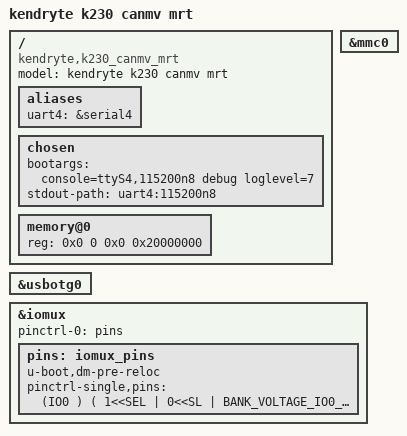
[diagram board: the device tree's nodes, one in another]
/* Copyright (c) 2023, Canaan Bright Sight Co., Ltd
 *
 * Redistribution and use in source and binary forms, with or without
 * modification, are permitted provided that the following conditions are met:
 * 1. Redistributions of source code must retain the above copyright
 * notice, this list of conditions and the following disclaimer.
 * 2. Redistributions in binary form must reproduce the above copyright
 * notice, this list of conditions and the following disclaimer in the
 * documentation and/or other materials provided with the distribution.
 *
 * THIS SOFTWARE IS PROVIDED BY THE COPYRIGHT HOLDERS AND
 * CONTRIBUTORS "AS IS" AND ANY EXPRESS OR IMPLIED WARRANTIES,
 * INCLUDING, BUT NOT LIMITED TO, THE IMPLIED WARRANTIES OF
 * MERCHANTABILITY AND FITNESS FOR A PARTICULAR PURPOSE ARE
 * DISCLAIMED. IN NO EVENT SHALL THE COPYRIGHT HOLDER OR
 * CONTRIBUTORS BE LIABLE FOR ANY DIRECT, INDIRECT, INCIDENTAL,
 * SPECIAL, EXEMPLARY, OR CONSEQUENTIAL DAMAGES (INCLUDING,
 * BUT NOT LIMITED TO, PROCUREMENT OF SUBSTITUTE GOODS OR
 * SERVICES; LOSS OF USE, DATA, OR PROFITS; OR BUSINESS
 * INTERRUPTION) HOWEVER CAUSED AND ON ANY THEORY OF LIABILITY,
 * WHETHER IN CONTRACT, STRICT LIABILITY, OR TORT (INCLUDING
 * NEGLIGENCE OR OTHERWISE) ARISING IN ANY WAY OUT OF THE USE
 * OF THIS SOFTWARE, EVEN IF ADVISED OF THE POSSIBILITY OF SUCH DAMAGE.
 */
/dts-v1/;
#include <dt-bindings/pinctrl/k230_evb.h>

/*
 * K230 CANMV MRT (K230_MAIN_1V3) board
 *
 * Bank voltage configuration from schematic K230_MAIN_1V3_20260420.pdf:
 *   IO0~IO1:   1V8 (fixed, OSPI domain)
 *   IO2~IO13:  1V8 (eMMC VCCQ=1V8, CAM0 I2C4=1V8)
 *   IO14~IO25: 3V3 (general IO, LCD, sensor)
 *   IO26~IO37: 1V8 (MMC1 WiFi SDIO, I2C3=1V8 domain per canmv_k230 ref)
 *   IO38~IO49: 3V3 (UART0, I2C1, GPIO)
 *   IO50~IO61: 3V3 (UART3, MMC1, WiFi)
 *   IO62~IO63: 1V8 (fixed)
 *
 * WARNING: Bank voltage MUST match board hardware.
 *          Incorrect configuration may permanently damage the chip!
 */
#define BANK_VOLTAGE_IO0_IO1	 K230_MSC_1V8
#define BANK_VOLTAGE_IO2_IO13	 K230_MSC_1V8
#define BANK_VOLTAGE_IO14_IO25	 K230_MSC_3V3
#define BANK_VOLTAGE_IO26_IO37	 K230_MSC_1V8
#define BANK_VOLTAGE_IO38_IO49	 K230_MSC_3V3
#define BANK_VOLTAGE_IO50_IO61	 K230_MSC_3V3
#define BANK_VOLTAGE_IO62_IO63	 K230_MSC_1V8
#include "k230.dtsi"

/ {
	model = "kendryte k230 canmv mrt";
	compatible = "kendryte,k230_canmv_mrt";

	aliases {
		uart4 = &serial4;
	};

	chosen {
		bootargs = "console=ttyS4,115200n8  debug loglevel=7";
		stdout-path = "uart4:115200n8";
	};

	memory@0 {
		device_type = "memory";
		reg = <
				0x0 0 0x0 0x20000000
			  >;
	};
};

&mmc0 {
	status = "okay";
};
&usbotg0 {
	status = "okay";
};
&iomux {
	pinctrl-names = "default";
	pinctrl-0 = <&pins>;

//	Please pay attention to the bank voltage! will damage the chip.
	pins: iomux_pins {
		u-boot,dm-pre-reloc;
		pinctrl-single,pins = <

		// OSPI CLK/DAT
		(IO0 ) ( 1<<SEL | 0<<SL | BANK_VOLTAGE_IO0_IO1 <<MSC | 1<<IE | 0<<OE | 0<<PU | 0<<PD | 0<<DS | 1<<ST )
		(IO1 ) ( 1<<SEL | 0<<SL | BANK_VOLTAGE_IO0_IO1 <<MSC | 1<<IE | 0<<OE | 0<<PU | 0<<PD | 0<<DS | 1<<ST )

		// JTAG / GPIO
		(IO2 ) ( 0<<SEL | 0<<SL | BANK_VOLTAGE_IO2_IO13 <<MSC | 1<<IE | 1<<OE | 0<<PU | 0<<PD | 7<<DS | 1<<ST )
		(IO3 ) ( 0<<SEL | 0<<SL | BANK_VOLTAGE_IO2_IO13 <<MSC | 1<<IE | 1<<OE | 0<<PU | 0<<PD | 7<<DS | 1<<ST )
		(IO4 ) ( 0<<SEL | 0<<SL | BANK_VOLTAGE_IO2_IO13 <<MSC | 1<<IE | 1<<OE | 0<<PU | 0<<PD | 7<<DS | 1<<ST )
		(IO5 ) ( 0<<SEL | 0<<SL | BANK_VOLTAGE_IO2_IO13 <<MSC | 1<<IE | 1<<OE | 0<<PU | 0<<PD | 7<<DS | 1<<ST )
		(IO6 ) ( 0<<SEL | 0<<SL | BANK_VOLTAGE_IO2_IO13 <<MSC | 1<<IE | 1<<OE | 0<<PU | 0<<PD | 7<<DS | 1<<ST )

		// CAM0_I2C4_SCL
		(IO7 ) ( 2<<SEL | 0<<SL | BANK_VOLTAGE_IO2_IO13 <<MSC | 1<<IE | 1<<OE | 0<<PU | 0<<PD | 7<<DS | 1<<ST )
		// CAM0_I2C4_SDA
		(IO8 ) ( 2<<SEL | 0<<SL | BANK_VOLTAGE_IO2_IO13 <<MSC | 1<<IE | 1<<OE | 0<<PU | 0<<PD | 7<<DS | 1<<ST )
		// CAM0_PWDN (GPIO9)
		(IO9 ) ( 0<<SEL | 0<<SL | BANK_VOLTAGE_IO2_IO13 <<MSC | 1<<IE | 1<<OE | 0<<PU | 0<<PD | 7<<DS | 1<<ST )
		// CAM0_RST (GPIO10)
		(IO10) ( 0<<SEL | 0<<SL | BANK_VOLTAGE_IO2_IO13 <<MSC | 1<<IE | 1<<OE | 0<<PU | 0<<PD | 7<<DS | 1<<ST )
		// GPIO11
		(IO11) ( 0<<SEL | 0<<SL | BANK_VOLTAGE_IO2_IO13 <<MSC | 1<<IE | 1<<OE | 0<<PU | 0<<PD | 7<<DS | 1<<ST )
		// GPIO12
		(IO12) ( 0<<SEL | 0<<SL | BANK_VOLTAGE_IO2_IO13 <<MSC | 1<<IE | 1<<OE | 0<<PU | 0<<PD | 7<<DS | 1<<ST )

		// CAM0_MCLK1
		(IO13) ( 1<<SEL | 0<<SL | BANK_VOLTAGE_IO2_IO13 <<MSC | 0<<IE | 1<<OE | 0<<PU | 0<<PD | 7<<DS | 0<<ST )

		// GPIO14 ~ GPIO16
		(IO14) ( 0<<SEL | 0<<SL | BANK_VOLTAGE_IO14_IO25 <<MSC | 1<<IE | 1<<OE | 0<<PU | 0<<PD | 7<<DS | 1<<ST )
		(IO15) ( 0<<SEL | 0<<SL | BANK_VOLTAGE_IO14_IO25 <<MSC | 1<<IE | 1<<OE | 0<<PU | 0<<PD | 7<<DS | 1<<ST )
		(IO16) ( 0<<SEL | 0<<SL | BANK_VOLTAGE_IO14_IO25 <<MSC | 1<<IE | 1<<OE | 0<<PU | 0<<PD | 7<<DS | 1<<ST )
		// LCD_BL (GPIO17)
		(IO17) ( 0<<SEL | 0<<SL | BANK_VOLTAGE_IO14_IO25 <<MSC | 1<<IE | 1<<OE | 0<<PU | 0<<PD | 15<<DS | 1<<ST )
		// GPIO18 ~ GPIO20
		(IO18) ( 0<<SEL | 0<<SL | BANK_VOLTAGE_IO14_IO25 <<MSC | 1<<IE | 1<<OE | 0<<PU | 0<<PD | 15<<DS | 1<<ST )
		(IO19) ( 0<<SEL | 0<<SL | BANK_VOLTAGE_IO14_IO25 <<MSC | 1<<IE | 1<<OE | 0<<PU | 0<<PD | 15<<DS | 1<<ST )
		(IO20) ( 0<<SEL | 0<<SL | BANK_VOLTAGE_IO14_IO25 <<MSC | 1<<IE | 1<<OE | 0<<PU | 0<<PD | 15<<DS | 1<<ST )
		// KEY (GPIO21)
		(IO21) ( 0<<SEL | 0<<SL | BANK_VOLTAGE_IO14_IO25 <<MSC | 1<<IE | 1<<OE | 0<<PU | 0<<PD | 15<<DS | 1<<ST )
		// TP_RST (GPIO22)
		(IO22) ( 0<<SEL | 0<<SL | BANK_VOLTAGE_IO14_IO25 <<MSC | 1<<IE | 1<<OE | 0<<PU | 0<<PD | 15<<DS | 1<<ST )
		// TP_INT (GPIO23)
		(IO23) ( 0<<SEL | 0<<SL | BANK_VOLTAGE_IO14_IO25 <<MSC | 1<<IE | 1<<OE | 0<<PU | 0<<PD | 15<<DS | 1<<ST )
		// LCD_RST (GPIO24)
		(IO24) ( 0<<SEL | 0<<SL | BANK_VOLTAGE_IO14_IO25 <<MSC | 1<<IE | 1<<OE | 0<<PU | 0<<PD | 15<<DS | 1<<ST )
		// FLASH_LED_PWM (GPIO25)
		(IO25) ( 0<<SEL | 0<<SL | BANK_VOLTAGE_IO14_IO25 <<MSC | 1<<IE | 1<<OE | 0<<PU | 0<<PD | 7<<DS | 1<<ST )

		// PDM_CLK (GPIO26)
		(IO26) ( 3<<SEL | 0<<SL | BANK_VOLTAGE_IO26_IO37 <<MSC | 0<<IE | 1<<OE | 0<<PU | 0<<PD | 7<<DS | 0<<ST )
		// PDM_DAT (GPIO27)
		(IO27) ( 0<<SEL | 0<<SL | BANK_VOLTAGE_IO26_IO37 <<MSC | 1<<IE | 1<<OE | 0<<PU | 0<<PD | 7<<DS | 1<<ST )
		// I2C3_SCL (touch/light sensor)
		(IO28) ( 3<<SEL | 0<<SL | BANK_VOLTAGE_IO26_IO37 <<MSC | 1<<IE | 0<<OE | 0<<PU | 0<<PD | 0<<DS | 1<<ST )
		// GPIO29 ~ GPIO31
		(IO29) ( 0<<SEL | 0<<SL | BANK_VOLTAGE_IO26_IO37 <<MSC | 1<<IE | 1<<OE | 0<<PU | 0<<PD | 7<<DS | 1<<ST )
		(IO30) ( 0<<SEL | 0<<SL | BANK_VOLTAGE_IO26_IO37 <<MSC | 1<<IE | 1<<OE | 0<<PU | 0<<PD | 7<<DS | 1<<ST )
		(IO31) ( 0<<SEL | 0<<SL | BANK_VOLTAGE_IO26_IO37 <<MSC | 1<<IE | 1<<OE | 0<<PU | 0<<PD | 7<<DS | 1<<ST )
		// MMC1_CMD (WiFi SDIO)
		(IO32) ( 0<<SEL | 0<<SL | BANK_VOLTAGE_IO26_IO37 <<MSC | 0<<IE | 1<<OE | 0<<PU | 0<<PD | 7<<DS | 1<<ST )
		// MMC1_CLK (WiFi SDIO)
		(IO33) ( 0<<SEL | 0<<SL | BANK_VOLTAGE_IO26_IO37 <<MSC | 0<<IE | 1<<OE | 0<<PU | 0<<PD | 7<<DS | 1<<ST )
		// MMC1_D0 (WiFi SDIO)
		(IO34) ( 1<<SEL | 0<<SL | BANK_VOLTAGE_IO26_IO37 <<MSC | 1<<IE | 1<<OE | 0<<PU | 0<<PD | 7<<DS | 1<<ST )
		// MMC1_D1 (WiFi SDIO)
		(IO35) ( 1<<SEL | 0<<SL | BANK_VOLTAGE_IO26_IO37 <<MSC | 1<<IE | 1<<OE | 0<<PU | 0<<PD | 7<<DS | 1<<ST )
		// I2C3_SDA (touch/light sensor)
		(IO36) ( 0<<SEL | 0<<SL | BANK_VOLTAGE_IO26_IO37 <<MSC | 1<<IE | 1<<OE | 0<<PU | 0<<PD | 7<<DS | 1<<ST )
		// GPIO37
		(IO37) ( 0<<SEL | 0<<SL | BANK_VOLTAGE_IO26_IO37 <<MSC | 1<<IE | 1<<OE | 0<<PU | 0<<PD | 7<<DS | 1<<ST )

		// UART0_TXD (DEBUG0)
		(IO38) ( 1<<SEL | 0<<SL | BANK_VOLTAGE_IO38_IO49 <<MSC | 0<<IE | 1<<OE | 0<<PU | 0<<PD | 7<<DS | 1<<ST )
		// UART0_RXD (DEBUG0)
		(IO39) ( 1<<SEL | 0<<SL | BANK_VOLTAGE_IO38_IO49 <<MSC | 1<<IE | 0<<OE | 0<<PU | 0<<PD | 7<<DS | 1<<ST )

		// GPIO40 ~ GPIO41
		(IO40) ( 0<<SEL | 0<<SL | BANK_VOLTAGE_IO38_IO49 <<MSC | 1<<IE | 1<<OE | 0<<PU | 0<<PD | 7<<DS | 1<<ST )
		(IO41) ( 0<<SEL | 0<<SL | BANK_VOLTAGE_IO38_IO49 <<MSC | 1<<IE | 1<<OE | 0<<PU | 0<<PD | 7<<DS | 1<<ST )

		// GPIO42 ~ GPIO43
		(IO42) ( 0<<SEL | 0<<SL | BANK_VOLTAGE_IO38_IO49 <<MSC | 1<<IE | 1<<OE | 0<<PU | 0<<PD | 7<<DS | 1<<ST )
		(IO43) ( 0<<SEL | 0<<SL | BANK_VOLTAGE_IO38_IO49 <<MSC | 1<<IE | 1<<OE | 0<<PU | 0<<PD | 7<<DS | 1<<ST )

		// UART2_TXD (BT)
		(IO44) ( 1<<SEL | 0<<SL | BANK_VOLTAGE_IO38_IO49 <<MSC | 0<<IE | 1<<OE | 0<<PU | 0<<PD | 7<<DS | 0<<ST )
		// UART2_RXD (BT)
		(IO45) ( 1<<SEL | 0<<SL | BANK_VOLTAGE_IO38_IO49 <<MSC | 1<<IE | 0<<OE | 0<<PU | 0<<PD | 0<<DS | 1<<ST )

		// UART4_TXD (EXTCON)
		(IO46) ( 0<<SEL | 0<<SL | BANK_VOLTAGE_IO38_IO49 <<MSC | 1<<IE | 1<<OE | 1<<PU | 0<<PD | 7<<DS | 1<<ST )
		// UART4_RXD (EXTCON)
		(IO47) ( 0<<SEL | 0<<SL | BANK_VOLTAGE_IO38_IO49 <<MSC | 1<<IE | 1<<OE | 1<<PU | 0<<PD | 7<<DS | 1<<ST )

		// uart4 tx,rx
		(IO48) ( 1<<SEL | 0<<SL | BANK_VOLTAGE_IO38_IO49 <<MSC | 0<<IE | 1<<OE | 0<<PU | 0<<PD | 7<<DS | 0<<ST )
		// I2C0_SDA
		(IO49) ( 1<<SEL | 0<<SL | BANK_VOLTAGE_IO38_IO49 <<MSC | 1<<IE | 0<<OE | 0<<PU | 0<<PD | 0<<DS | 1<<ST )

		// UART3_TXD (DEBUG1)
		(IO50) ( 1<<SEL | 0<<SL | BANK_VOLTAGE_IO50_IO61 <<MSC | 0<<IE | 1<<OE | 0<<PU | 0<<PD | 7<<DS | 1<<ST )
		// UART3_RXD (DEBUG1)
		(IO51) ( 1<<SEL | 0<<SL | BANK_VOLTAGE_IO50_IO61 <<MSC | 1<<IE | 0<<OE | 0<<PU | 0<<PD | 7<<DS | 1<<ST )

		// I2C1_SCL (CAM1)
		(IO52) ( 3<<SEL | 0<<SL | BANK_VOLTAGE_IO50_IO61 <<MSC | 1<<IE | 1<<OE | 0<<PU | 0<<PD | 7<<DS | 1<<ST )
		// I2C1_SDA (CAM1)
		(IO53) ( 3<<SEL | 0<<SL | BANK_VOLTAGE_IO50_IO61 <<MSC | 1<<IE | 1<<OE | 0<<PU | 0<<PD | 7<<DS | 1<<ST )

		// MMC1_D2 (WiFi SDIO)
		(IO54) ( 2<<SEL | 0<<SL | BANK_VOLTAGE_IO50_IO61 <<MSC | 1<<IE | 1<<OE | 1<<PU | 0<<PD | 7<<DS | 1<<ST )
		// MMC1_D3 (WiFi SDIO)
		(IO55) ( 2<<SEL | 0<<SL | BANK_VOLTAGE_IO50_IO61 <<MSC | 0<<IE | 1<<OE | 0<<PU | 0<<PD | 7<<DS | 1<<ST )
		// MMC1_CLK
		(IO56) ( 2<<SEL | 0<<SL | BANK_VOLTAGE_IO50_IO61 <<MSC | 1<<IE | 1<<OE | 1<<PU | 0<<PD | 7<<DS | 1<<ST )
		// MMC1_CMD
		(IO57) ( 2<<SEL | 0<<SL | BANK_VOLTAGE_IO50_IO61 <<MSC | 1<<IE | 1<<OE | 1<<PU | 0<<PD | 7<<DS | 1<<ST )
		// MMC1_D0
		(IO58) ( 2<<SEL | 0<<SL | BANK_VOLTAGE_IO50_IO61 <<MSC | 1<<IE | 1<<OE | 1<<PU | 0<<PD | 7<<DS | 1<<ST )
		// MMC1_D1
		(IO59) ( 2<<SEL | 0<<SL | BANK_VOLTAGE_IO50_IO61 <<MSC | 1<<IE | 1<<OE | 1<<PU | 0<<PD | 7<<DS | 1<<ST )
		// MMC1_D2
		(IO60) ( 2<<SEL | 0<<SL | BANK_VOLTAGE_IO50_IO61 <<MSC | 1<<IE | 1<<OE | 0<<PU | 0<<PD | 7<<DS | 1<<ST )
		// MMC1_D3
		(IO61) ( 2<<SEL | 0<<SL | BANK_VOLTAGE_IO50_IO61 <<MSC | 1<<IE | 1<<OE | 0<<PU | 0<<PD | 7<<DS | 1<<ST )

		// CAM2_RST (GPIO62)
		(IO62) ( 1<<SEL | 0<<SL | BANK_VOLTAGE_IO62_IO63 <<MSC | 0<<IE | 1<<OE | 0<<PU | 0<<PD | 7<<DS | 0<<ST )
		// CAM2_MCLK (GPIO63)
		(IO63) ( 0<<SEL | 0<<SL | BANK_VOLTAGE_IO62_IO63 <<MSC | 1<<IE | 1<<OE | 0<<PU | 0<<PD | 7<<DS | 1<<ST )
		>;
	};
};
